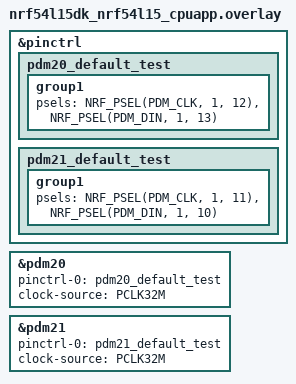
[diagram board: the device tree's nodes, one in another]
/*
 * Copyright (c) 2025 Nordic Semiconductor ASA
 *
 * SPDX-License-Identifier: LicenseRef-Nordic-5-Clause
 */

/* Test requires loopbacks:
 * - between P1.12 and P1.13,
 * - between P1.11 and P1.10.
 * For best performance, PDM_CLK shall be on 'Clock pin'.
 */

&pinctrl {
	pdm20_default_test: pdm20_default_test {
		group1 {
			psels = <NRF_PSEL(PDM_CLK, 1, 12)>,
				<NRF_PSEL(PDM_DIN, 1, 13)>;
		};
	};

	pdm21_default_test: pdm21_default_test {
		group1 {
			psels = <NRF_PSEL(PDM_CLK, 1, 11)>,
				<NRF_PSEL(PDM_DIN, 1, 10)>;
		};
	};
};

&pdm20 {
	status = "okay";
	pinctrl-0 = <&pdm20_default_test>;
	pinctrl-names = "default";
	clock-source = "PCLK32M";
};

&pdm21 {
	status = "okay";
	pinctrl-0 = <&pdm21_default_test>;
	pinctrl-names = "default";
	clock-source = "PCLK32M";
};
